# cc13x2_cc26x2 register map
File version: 2.1
CPU: CM4 r0p1, little endian, MPU, FPU, 3 interrupt priority bits
Registers are 32-bit, read-write, reset 0x0 unless marked. A register's access mark holds for its fields unless they carry their own. Offsets are from the block's base; [hi:lo] are bit positions; {n}, {i} and the like mark numbered series.

## AUX_TDC — AUX Time To Digital Converter (AUX_TDC) is used to measure the time between two events with high resolution. UX_TDC consists of a state machine that operates at AUX bus rate and an asynchronous fast-counter which is clocked by the TDC clock. DDI_0_OSC:CTL0.ACLK_TDC_SRC_SEL configures TDC clock source. The fast-counter counts on both edges of the TDC clock to double the resolution. ee the Technical Reference Manual for event timing requirements.
Base 0x400C4000
0x00 CTL — Control
  [1:0] CMD
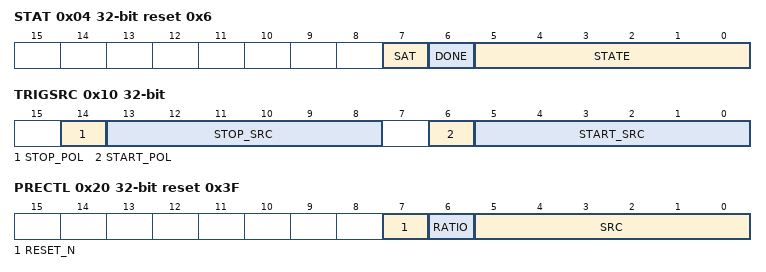
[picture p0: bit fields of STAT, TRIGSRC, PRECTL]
0x04 STAT ro reset 0x6 — Status
  [7] SAT, [6] DONE, [5:0] STATE
0x08 RESULT ro reset 0x2 — Result esult of last TDC conversion.
  [24:0] VALUE
0x0C SATCFG reset 0xF — Saturation Configuration
  [3:0] LIMIT
0x10 TRIGSRC — Trigger Source elect source and polarity for TDC start and stop events. See the Technical Reference Manual for event timing requirements.
  [14] STOP_POL, [13:8] STOP_SRC, [6] START_POL, [5:0] START_SRC
0x14 TRIGCNT — Trigger Counter top-counter control and status.
  [15:0] CNT
0x18 TRIGCNTLOAD — Trigger Counter Load top-counter load.
  [15:0] CNT
0x1C TRIGCNTCFG — Trigger Counter Configuration top-counter configuration.
  [0] EN
0x20 PRECTL reset 0x3F — Prescaler Control he prescaler can be used to count events that are faster than the AUX bus rate. t can be used to: count pulses on a specified event from the asynchronous event bus. prescale a specified event from the asynchronous event bus. o use the prescaler output as an event source in TDC measurements you must set both TRIGSRC.START_SRC and TRIGSRC.STOP_SRC to AUX_TDC_PRE. t is recommended to use the prescaler when the signal frequency to measure exceeds 1/10th of the AUX bus rate.
  [7] RESET_N, [6] RATIO, [5:0] SRC
0x24 PRECNTR — Prescaler Counter
  [15:0] CNT

## AUX_TIMER01 — AUX Timer 0 and AUX Timer 1 (AUX_TIMER01) are two 16-bit timers capable of generating one event each: AUX_EVCTL:EVSTAT3.AUX_TIMER0_EV. AUX_EVCTL:EVSTAT3.AUX_TIMER1_EV. he events are described in T0TARGET and T1TARGET. Subscribers to the AUX event bus can use these events to sequence and trigger actions. UX_SYSIF:PEROPRATE.TIMER01_OP_RATE sets the peripheral clock frequency used by the prescaler, timer, and event logic to SCE or AUX bus rate. To use AUX_TIMER01: AUX_SCE must set AUX_SYSIF:PEROPRATE.TIMER01_OP_RATE to SCE_RATE. System CPU must set AUX_SYSIF:PEROPRATE.TIMER01_OP_RATE to BUS_RATE. The timers must only subscribe to events updated at the peripheral clock frequency or lower. nexpected execution behavior can result if software does not obey these rules.
Base 0x400C7000
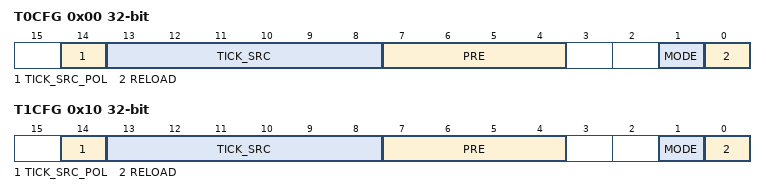
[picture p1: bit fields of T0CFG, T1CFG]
0x00 T0CFG — Timer 0 Configuration
  [14] TICK_SRC_POL, [13:8] TICK_SRC, [7:4] PRE, [1] MODE, [0] RELOAD
0x04 T0CTL — Timer 0 Control
  [0] EN
0x08 T0TARGET — Timer 0 Target
  [15:0] VALUE
0x0C T0CNTR ro — Timer 0 Counter
  [15:0] VALUE
0x10 T1CFG — Timer 1 Configuration
  [14] TICK_SRC_POL, [13:8] TICK_SRC, [7:4] PRE, [1] MODE, [0] RELOAD
0x14 T1CTL — Timer 1 Control
  [0] EN
0x18 T1TARGET — Timer 1 Target imer 1 counter target value
  [15:0] VALUE
0x1C T1CNTR ro — Timer 1 Counter
  [15:0] VALUE

## AUX_TIMER2 — AUX Timer2 (AUX_TIMER2) offers flexible: generation of waveforms and events. capture of signal period and duty cycle. generation of single clock pulse. t consists of a: 16-bit counter. 4 capture compare channels. 4 event outputs, which are mapped to AUX event bus, see EVCTL. ach channel subscribes to the asynchronous AUX event bus. They can control one or more event outputs in both capture and compare modes. AUX_SYSIF:TIMER2CLKCTL.SRC selects clock source for the timer.
Base 0x400C3000
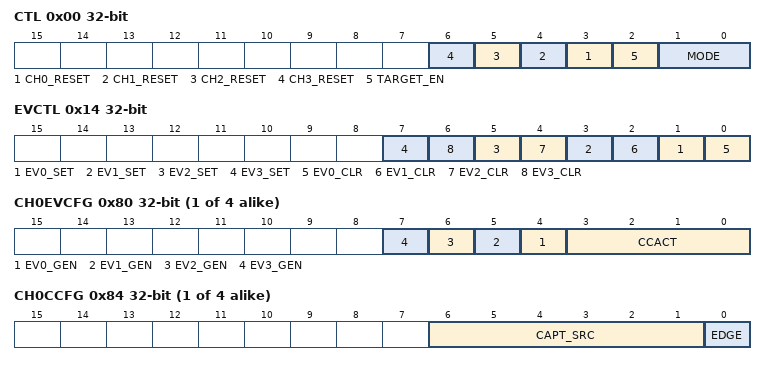
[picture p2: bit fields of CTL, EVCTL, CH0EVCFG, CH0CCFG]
0x00 CTL — Timer Control
  [n+3] CH{n}_RESET (n=0..3), [2] TARGET_EN, [1:0] MODE
0x04 TARGET — Target ser defined counter target.
  [15:0] VALUE
0x08 SHDWTARGET — Shadow Target
  [15:0] VALUE
0x0C CNTR ro — Counter
  [15:0] VALUE
0x10 PRECFG — Clock Prescaler Configuration
  [7:0] CLKDIV
0x14 EVCTL wo — Event Control et and clear individual events manually. Manual update of an event takes priority over automatic channel updates to the same event. You cannot set and clear an event at the same time, such requests will be neglected. n event can be automatically cleared, set, toggled, or pulsed by each channel, listed in decreasing order of priority. The action with highest priority happens when multiple channels want to update an event at the same time. he four events connect to the asynchronous AUX event bus: Event 0 connects to AUX_EVCTL:EVSTAT3.AUX_TIMER2_EV0. Event 1 connects to AUX_EVCTL:EVSTAT3.AUX_TIMER2_EV1. Event 2 connects to AUX_EVCTL:EVSTAT3.AUX_TIMER2_EV2. Event 3 connects to AUX_EVCTL:EVSTAT3.AUX_TIMER2_EV3.
  [2n+1] EV{n}_SET (n=0..3), [2n] EV{n}_CLR (n=0..3)
0x18 PULSETRIG — Pulse Trigger
  [0] TRIG
{0x80+0x10*i} CH{i}EVCFG (i=0..3) — Channel {i} Event Configuration his register configures channel function and enables event outputs. ach channel has an edge-detection circuit with memory. The circuit is: - enabled while CCACT selects a capture function and CTL.MODE is different from DIS. - flushed while CCACT selects a capture function and you change CTL.MODE from DIS to another mode. he flush action uses two AUX_SYSIF:TIMER2CLKCTL.SRC clock periods. It prevents capture events caused by expired signal values stored in the edge-detection circuit.
  [n+4] EV{n}_GEN (n=0..3), [3:0] CCACT
{0x84+0x10*i} CH{i}CCFG (i=0..3) — Channel {i} Capture Configuration
  [6:1] CAPT_SRC, [0] EDGE
{0x88+0x10*i} CH{i}PCC (i=0..3) — Channel {i} Pipeline Capture Compare
  [15:0] VALUE
{0x8C+0x10*i} CH{i}CC (i=0..3) — Channel {i} Capture Compare
  [15:0] VALUE
